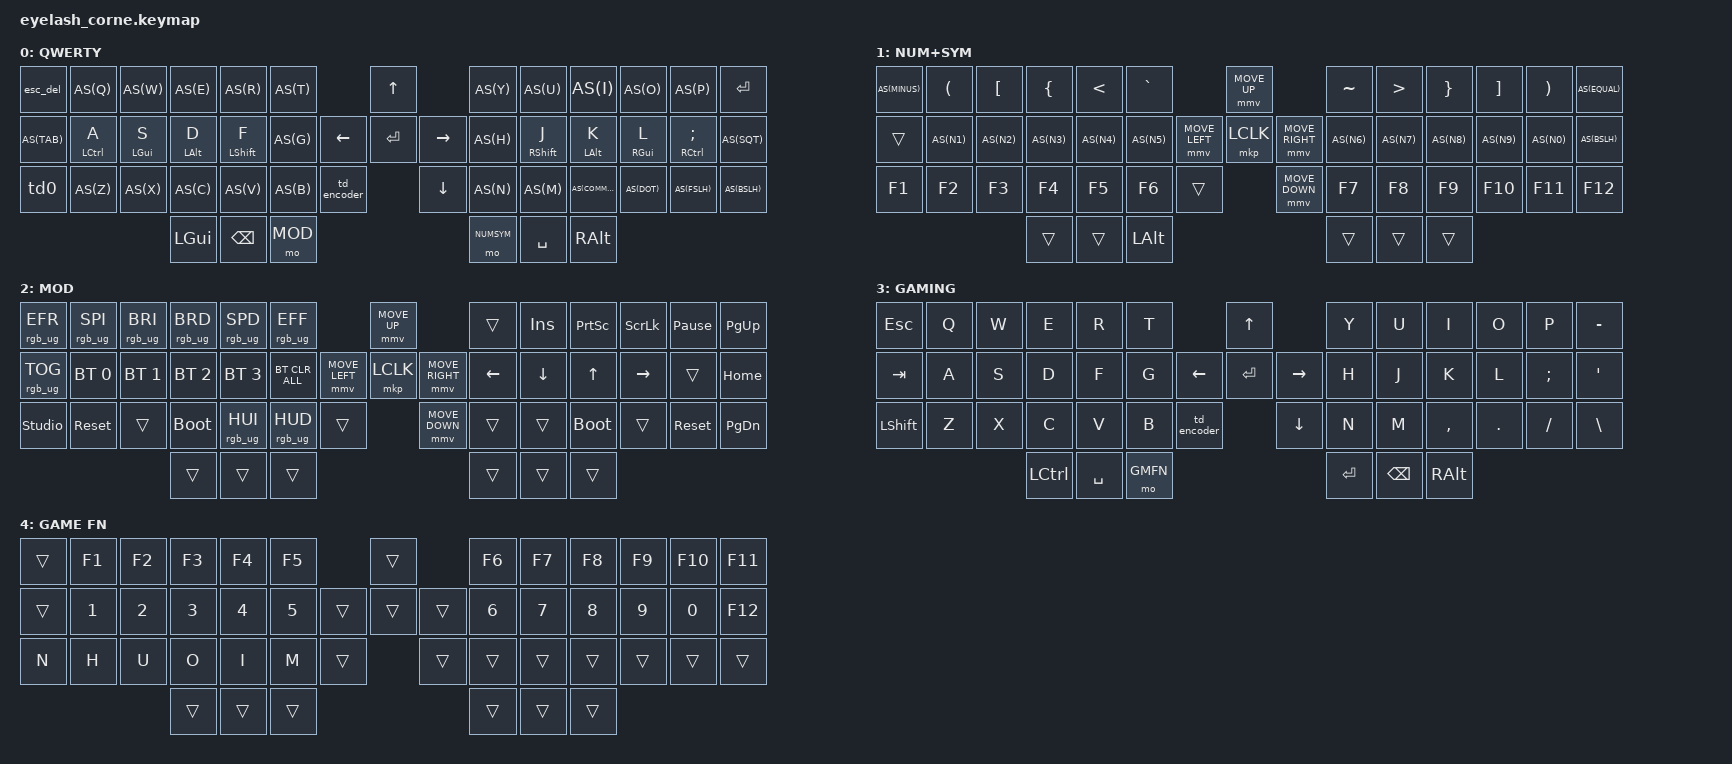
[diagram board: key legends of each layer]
// ============================================================================
// INCLUDES
// ============================================================================
#include <behaviors.dtsi>
#include <dt-bindings/zmk/keys.h>
#include <dt-bindings/zmk/bt.h>
#include <dt-bindings/zmk/outputs.h>
#include <dt-bindings/zmk/rgb.h>
#include <dt-bindings/zmk/pointing.h>
#include <input/processors.dtsi>
#include <zephyr/dt-bindings/input/input-event-codes.h>

// ============================================================================
// LAYER DEFINITIONS
// ============================================================================
#define DFLT 0
/* #define NUM 1 */
/* #define SYM 2 */
#define NUMSYM 1
/* #define MOD 3 */
#define MOD 2
/* #define GMNG 4 */
#define GMNG 3
/* #define GMFN 5 */
#define GMFN 4

// ============================================================================
// CONFIGURATION
// ============================================================================
#undef ZMK_POINTING_DEFAULT_MOVE_VAL
#define ZMK_POINTING_DEFAULT_MOVE_VAL 1200  // 600
#undef ZMK_POINTING_DEFAULT_SCRL_VAL
#define ZMK_POINTING_DEFAULT_SCRL_VAL 25    // 10

// ============================================================================
// MACROS
// ============================================================================
#define AS(keycode) &as LS(keycode) keycode     // Autoshift Macro

// ============================================================================
// INPUT LISTENERS
// ============================================================================
&mmv_input_listener { input-processors = <&zip_xy_scaler 2 1>; };

&msc_input_listener { input-processors = <&zip_scroll_scaler 2 1>; };

// ============================================================================
// MOUSE SCROLL CONFIGURATION
// ============================================================================
&msc {
    acceleration-exponent = <1>;      // 0
    time-to-max-speed-ms = <100>;     // 300
    delay-ms = <0>;                   // 0
};

// ============================================================================
// MOUSE MOVEMENT CONFIGURATION
// ============================================================================
&mmv {
    time-to-max-speed-ms = <500>;
    acceleration-exponent = <1>;
    trigger-period-ms = <16>;
};

// // ============================================================================
// // ENCODER CONFIGURATION
// // ============================================================================
// &sensors {
//     compatible = "alps,ec11";
//     steps = <30>;
// };

// ============================================================================
// SOFT OFF CONFIGURATION
// ============================================================================
&soft_off { hold-time-ms = <2000>; };

// ============================================================================
// Layout Numbering
// ============================================================================
// 0=td_esc   1=Q      2=W      3=E      4=R      5=T      6=UP      7=Y      8=U      9=I     10=O     11=P     12=ENTER
// 13=TAB     14=A     15=S     16=D     17=F     18=G     19=LEFT   20=ENTER 21=RIGHT 22=H     23=J     24=K     25=L     26=;     27='
// 28=td0     29=Z     30=X     31=C     32=V     33=B     34=td_enc 35=DOWN           36=N     37=M     38=,     39=.     40=/     41=\
//                                       42=GUI   43=BSPC  44=MOD                      45=NUMSYM 46=SPACE 47=ALT

// ============================================================================
// DEVICE TREE ROOT
// ============================================================================
/ {
    macros {
        // Ctrl+Alt+Del macro
        cad: ctrl_alt_del {
            compatible = "zmk,behavior-macro";
            #binding-cells = <0>;
            bindings = <&kp LC(LA(DEL))>;
        };
    };

    behaviors {
        // Auto Shift
        as: auto_shift {
            compatible = "zmk,behavior-hold-tap";
            #binding-cells = <2>;
            tapping_term_ms = <175>;
            quick_tap_ms = <0>;
            flavor = "tap-preferred";
            bindings = <&kp>, <&kp>;
        };

        // Home Row Mods
        hml: home_row_mod_left {
            compatible = "zmk,behavior-hold-tap";
            #binding-cells = <2>;
            flavor = "balanced";
            require-prior-idle-ms = <150>;
            tapping-term-ms = <280>;
            quick-tap-ms = <175>;
            bindings = <&kp>, <&kp>;
            // Right side keys (positions 6-12, 19-27, 34-41, 45-47)
            hold-trigger-key-positions = <6 7 8 9 10 11 12 19 20 21 22 23 24 25 26 27 34 35 36 37 38 39 40 41 45 46 47>;
            hold-trigger-on-release;
        };
        hmr: home_row_mod_right {
            compatible = "zmk,behavior-hold-tap";
            #binding-cells = <2>;
            flavor = "balanced";
            require-prior-idle-ms = <150>;
            tapping-term-ms = <280>;
            quick-tap-ms = <175>;
            bindings = <&kp>, <&kp>;
            // Left side keys (positions 0-5, 13-18, 28-33, 42-44)
            hold-trigger-key-positions = <0 1 2 3 4 5 13 14 15 16 17 18 28 29 30 31 32 33 42 43 44>;
            hold-trigger-on-release;
        };

        // escape/delete mod-morph
        esc_del: esc_del {
            compatible = "zmk,behavior-mod-morph";
            #binding-cells = <0>;
            bindings = <&kp ESC>, <&kp DEL>;
            mods = <(MOD_LSFT|MOD_RSFT)>;
        };

        // Tap Dance
        td0: td0 {
            compatible = "zmk,behavior-tap-dance";
            display-name = "Shift/Caps Lock Tap Dance";
            #binding-cells = <0>;
            tapping-term-ms = <280>;
            bindings = <&kp LEFT_SHIFT>, <&kp CAPS>;
        };
        td_esc: td_esc {
            compatible = "zmk,behavior-tap-dance";
            display-name = "ESC/Delete Tap Dance";
            #binding-cells = <0>;
            tapping-term-ms = <280>;
            bindings = <&kp ESC>, <&kp DEL>;
        };
        td_encoder: td_encoder {
            compatible = "zmk,behavior-tap-dance";
            display-name = "Encoder Mute/Pause Tap Dance";
            #binding-cells = <0>;
            tapping-term-ms = <280>;
            bindings = <&kp K_PLAY_PAUSE>, <&kp K_MUTE>;
        };


        // Encoder behaviors
        rgb_encoder: rgb_encoder {
            compatible = "zmk,behavior-sensor-rotate";
            #sensor-binding-cells = <0>;
            bindings = <&rgb_ug RGB_BRI>, <&rgb_ug RGB_BRD>;
        };
        scroll_encoder: scroll_encoder {
            compatible = "zmk,behavior-sensor-rotate";
            #sensor-binding-cells = <0>;
            bindings = <&msc SCRL_DOWN>, <&msc SCRL_UP>;

            // tap-ms = <50>;
        };
    };

    combos {
        compatible = "zmk,combos";

        softoff {
            bindings = <&soft_off>;
            key-positions = <1 15 29>;
        };

        gaming_toggle {
            bindings = <&tog GMNG>;
            key-positions = <43 46>;  // both layer keys
            timeout-ms = <50>;
            layers = <0 3>;
        };

        ctrl_alt_del_combo {
            bindings = <&cad>;
            key-positions = <23 24 25>; // three finger salute
            timeout-ms = <50>;
            layers = <0>;
        };

        undo_combo {
            bindings = <&kp LC(Z)>;  // Ctrl+Z
            key-positions = <28 29>; // Shift+Z
            timeout-ms = <50>;
            layers = <0>;
        };

        redo_combo {
            bindings = <&kp LC(LS(Z))>;  // Ctrl+Shift+Z
            key-positions = <28 33>; // Shift+B
            timeout-ms = <50>;
            layers = <0>;
        };

        cut_combo {
            bindings = <&kp LC(LS(X))>;  // Ctrl+Shift+X
            key-positions = <28 30>; // Shift+X
            timeout-ms = <50>;
            layers = <0>;
        };

        copy_combo {
            bindings = <&kp LC(LS(C))>;  // Ctrl+Shift+C
            key-positions = <28 31>; // Shift+C
            timeout-ms = <50>;
            layers = <0>;
        };

        paste_combo {
            bindings = <&kp LC(LS(V))>;  // Ctrl+Shift+V
            key-positions = <28 32>; // Shift+V
            timeout-ms = <50>;
            layers = <0>;
        };
    };

    keymap {
        compatible = "zmk,keymap";

        default_layer {
            display-name = "QWERTY";
            bindings = <
                // ╭─────────┬──────────────┬──────────────┬──────────────┬──────────────┬──────────────╮                   ╭───────────────╮                   ╭────────────┬─────────────┬───────────┬───────────┬─────────────┬───────────╮
                     &esc_del      AS(Q)          AS(W)          AS(E)          AS(R)          AS(T)                              &kp UP                           AS(Y)          AS(U)        AS(I)      AS(O)        AS(P)       &kp ENTER
                // │ES/DL/CAD│      Q       │      W       │      E       │      R       │      T       │                   │       ↑       │                   │    Y       │      U      │     I     │    O      │     P       │ ENTER     │
                // ├─────────┼──────────────┼──────────────┼──────────────┼──────────────┼──────────────┤ ╭─────────────────┼───────────────┼─────────────────╮ ├────────────┼─────────────┼───────────┼───────────┼─────────────┼───────────┤
                     AS(TAB)   &hml LCTRL A    &hml LGUI S    &hml LALT D   &hml LSHIFT F   AS(G)              &kp LEFT          &kp ENTER       &kp RIGHT         AS(H)      &hmr RSHIFT J &hmr LALT K &hmr RGUI L &hmr RCTRL SEMI  AS(SQT)
                // │  TAB    │   A/CTRL     │   S/GUI      │    D/ALT     │   F/SHIFT    │      G       │ │        ←        │     ENTER     │        →        │ │    H       │   J/SHIFT   │   K/ALT   │  L/GUI    │     ;/CTRL  │     '     │
                // ├─────────┼──────────────┼──────────────┼──────────────┼──────────────┼──────────────┤ ╰─────────────────┼───────────────┼─────────────────╯ ├────────────┼─────────────┼───────────┼───────────┼─────────────┼───────────┤
                     &td0         AS(Z)          AS(X)          AS(C)          AS(V)          AS(B)         &td_encoder         &kp DOWN                          AS(N)          AS(M)       AS(COMMA)    AS(DOT)      AS(FSLH)     AS(BSLH)
                // │ SHIFT/CL│      Z       │      X       │      C       │      V       │      B       │    PLAY/MUTE      │       ↓       │                   │    N       │      M      │      ,    │     .     │      /      │     \     │
                // ╰─────────┴──────────────┴──────────────┼──────────────┼──────────────┼──────────────┤                   ╰───────────────╯                   ├────────────┼─────────────┼───────────┼───────────┴─────────────┴───────────╯
                                                                &kp LGUI       &kp BSPC        &mo MOD                                                            &mo NUMSYM    &kp SPACE     &kp RALT
                //                                         │      GUI     │     BSPC     │   LAYER2     │                                                       │ LAYER1     │    SPACE    │    ALT    │
                //                                         ╰──────────────┴──────────────┴──────────────╯                                                       ╰────────────┴─────────────┴───────────╯
            >;

            sensor-bindings = <&inc_dec_kp C_VOL_UP C_VOL_DN>;  // 🔊 Volume control
        };

        numsym_layer {
            display-name = "NUM+SYM";
            bindings = <
                // ╭────────┬──────────┬──────────┬──────────┬────────┬───────────╮                   ╭───────────────╮                   ╭───────────┬────────┬──────────┬──────────┬──────────┬───────────╮
                   AS(MINUS)  &kp LPAR   &kp LBKT   &kp LBRC   &kp LT   &kp GRAVE                        &mmv MOVE_UP                       &kp TILDE   &kp GT   &kp RBRC   &kp RBKT   &kp RPAR   AS(EQUAL)
                // │ - / _  │     (    │     [    │    {     │   <    │     `     │                   │       ↑       │                   │      ~    │    >   │     }    │     ]    │     )    │   = / +   │
                // ├────────┼──────────┼──────────┼──────────┼────────┼───────────┤ ╭─────────────────┼───────────────┼─────────────────╮ ├───────────┼────────┼──────────┼──────────┼──────────┼───────────┤
                     &trans    AS(N1)     AS(N2)     AS(N3)     AS(N4)    AS(N5)       &mmv MOVE_LEFT     &mkp LCLK     &mmv MOVE_RIGHT      AS(N6)     AS(N7)    AS(N8)     AS(N9)     AS(N0)    AS(BSLH)
                // │  TAB   │  1 / !   │  2 / @   │  3 / #   │  4 / $ │   5 / %   │ │        ←        │     CLICK     │        →        │ │   6 / ^   │  7 / & │   8 / *  │   9 / (  │   0 / )  │   \ / |   │
                // ├────────┼──────────┼──────────┼──────────┼────────┼───────────┤ ╰─────────────────┼───────────────┼─────────────────╯ ├───────────┼────────┼──────────┼──────────┼──────────┼───────────┤
                     &kp F1    &kp F2     &kp F3     &kp F4     &kp F5    &kp F6           &trans         &mmv MOVE_DOWN                     &kp F7     &kp F8    &kp F9     &kp F10    &kp F11    &kp F12
                // │   F1   │    F2    │    F3    │    F4    │     F5 │      F6   │    PLAY/MUTE      │       ↓       │                   │     F7    │    F8  │     F9   │     F10  │     F11  │     F12   │
                // ╰────────┴──────────┴──────────┼──────────┼────────┼───────────┤                   ╰───────────────╯                   ├───────────┼────────┼──────────┼──────────┴──────────┴───────────╯
                                                     &trans    &trans   &kp LALT                                                             &trans     &trans    &trans
                //                                │      GUI │   BSPC │   LALT    │                                                       │   ^^^^    │ SPACE  │   ALT    │
                //                                ╰──────────┴────────┴───────────╯                                                       ╰───────────┴────────┴──────────╯
            >;

            sensor-bindings = <&inc_dec_kp C_BRI_UP C_BRI_DN>;  // 🔆 Brightness control
        };

        mod_layer {
            display-name = "MOD";
            bindings = <
                // ╭───────────────┬───────────────┬───────────────┬───────────────┬───────────────┬───────────────╮                  ╭───────────────╮                   ╭────────┬────────┬──────────────┬──────────────┬──────────────┬──────────╮
                    &rgb_ug RGB_EFR &rgb_ug RGB_SPI &rgb_ug RGB_BRI &rgb_ug RGB_BRD &rgb_ug RGB_SPD &rgb_ug RGB_EFF                     &mmv MOVE_UP                        &trans  &kp INS &kp PRINTSCREEN &kp SCROLLLOCK &kp PAUSE_BREAK &kp PG_UP
                // │   RGB EFR     │   RGB SPI     │   RGB BRI     │   RGB BRD     │    RGB SPD    │    RGB EFF    │                  │       ↑       │                   │  ---   │ INS    │   PRTSCRN    │   SCRLCK     │ PAUSE BREAK  │  PG UP   │
                // ├───────────────┼───────────────┼───────────────┼───────────────┼───────────────┼───────────────┤ ╭────────────────┼───────────────┼─────────────────╮ ├────────┼────────┼──────────────┼──────────────┼──────────────┼──────────┤
                    &rgb_ug RGB_TOG  &bt BT_SEL 0    &bt BT_SEL 1     &bt BT_SEL 2    &bt BT_SEL 3   &bt BT_CLR_ALL    &mmv MOVE_LEFT     &mkp LCLK     &mmv MOVE_RIGHT    &kp LEFT &kp DOWN    &kp UP         &kp RIGHT      &trans       &kp HOME
                // │   RGB TOG     │    BT 0       │    BT 1       │     BT 2      │     BT 3      │     BT CLR    │ │       ←        │     CLICK     │        →        │ │    ←   │    ↓   │       ↑      │       →      │     ---      │   HOME   │
                // ├───────────────┼───────────────┼───────────────┼───────────────┼───────────────┼───────────────┤ ╰────────────────┼───────────────┼─────────────────╯ ├────────┼────────┼──────────────┼──────────────┼──────────────┼──────────┤
                    &studio_unlock    &sys_reset       &trans        &bootloader    &rgb_ug RGB_HUI &rgb_ug RGB_HUD     &trans          &mmv MOVE_DOWN                      &trans   &trans    &bootloader      &trans        &sys_reset   &kp PG_DN
                // │STUDIO UNLOCK  │  SYS RST      │   ---         │  BOOTLOADER   │    RGB HUI    │    RGB HUD    │   PLAY/MUTE      │       ↓       │                   │  ---   │  ---   │ BOOTLOADER   │     ---      │   SYS RST    │   PG DN  │
                // ╰───────────────┴───────────────┴───────────────┼───────────────┼───────────────┼───────────────┤                  ╰───────────────╯                   ├────────┼────────┼──────────────┼──────────────┴──────────────┴──────────╯
                                                                         &trans           &trans         &trans                                                             &trans   &trans      &trans
                //                                                 │     ^^^^      │      BSPC     │      MOD      │                                                      │SYMLAYER│ SPACE  │     ALT      │
                //                                                 ╰───────────────┴───────────────┴───────────────╯                                                      ╰────────┴────────┴──────────────╯
            >;

            sensor-bindings = <&scroll_encoder>;  // 📜 Scroll control
        };

        gaming_layer {
            display-name = "GAMING";
            bindings = <
                // ╭────────┬────────┬────────┬────────┬────────┬────────╮                   ╭───────────────╮                   ╭────────┬────────┬────────┬────────┬────────┬────────╮
                    &kp ESC   &kp Q    &kp W    &kp E    &kp R    &kp T                            &kp UP                          &kp Y    &kp U    &kp I    &kp O    &kp P    &kp MINUS
                // │  ESC   │   Q    │   W    │   E    │   R    │   T    │                   │       ↑       │                   │   Y    │   U    │   I    │   O    │   P    │   -    │
                // ├────────┼────────┼────────┼────────┼────────┼────────┤ ╭─────────────────┼───────────────┼─────────────────╮ ├────────┼────────┼────────┼────────┼────────┼────────┤
                     &kp TAB  &kp A    &kp S    &kp D    &kp F    &kp G        &kp LEFT          &kp ENTER      &kp RIGHT          &kp H    &kp J    &kp K    &kp L    &kp SEMI &kp SQT
                // │  TAB   │   A    │   S    │   D    │   F    │   G    │ │        ←        │     ENTER     │        →        │ │   H    │   J    │   K    │   L    │   ;    │   '    │
                // ├────────┼────────┼────────┼────────┼────────┼────────┤ ╰─────────────────┼───────────────┼─────────────────╯ ├────────┼────────┼────────┼────────┼────────┼────────┤
                     &kp LSHIFT &kp Z  &kp X    &kp C    &kp V    &kp B        &td_encoder       &kp DOWN                          &kp N    &kp M    &kp COMMA &kp DOT &kp FSLH &kp BSLH
                // │ SHIFT  │   Z    │   X    │   C    │   V    │   B    │       MUTE        │       ↓       │                   │   N    │   M    │   ,    │   .    │   /    │   \    │
                // ╰────────┴────────┴────────┼────────┼────────┼────────┤                   ╰───────────────╯                   ├────────┼────────┼────────┼────────┴────────┴────────╯
                                                &kp LCTRL &kp SPACE &mo GMFN                                                       &kp ENTER &kp BSPC &kp RALT
                //                            │  CTRL  │  SPACE │ GAMEFN │                                                       │ ENTER  │  BSPC  │  ALT   │
                //                            ╰────────┴────────┴────────╯                                                       ╰────────┴────────┴────────╯
            >;

            sensor-bindings = <&scroll_encoder>;  // 📜 Scroll control
        };

        gaming_fn_layer {
            display-name = "GAME FN";
            bindings = <
                // ╭────────┬────────┬────────┬────────┬────────┬────────╮                   ╭───────────────╮                   ╭────────┬────────┬────────┬────────┬────────┬────────╮
                     &trans   &kp F1   &kp F2   &kp F3   &kp F4   &kp F5                         &trans                            &kp F6   &kp F7   &kp F8   &kp F9   &kp F10  &kp F11
                // │  ESC   │   F1   │   F2   │   F3   │   F4   │   F5   │                   │       ↑       │                   │   F6   │   F7   │   F8   │   F9   │  F10   │  F11   │
                // ├────────┼────────┼────────┼────────┼────────┼────────┤ ╭─────────────────┼───────────────┼─────────────────╮ ├────────┼────────┼────────┼────────┼────────┼────────┤
                     &trans   &kp N1   &kp N2   &kp N3   &kp N4   &kp N5       &trans           &trans           &trans            &kp N6   &kp N7   &kp N8   &kp N9   &kp N0   &kp F12
                // │  TAB   │   1    │   2    │   3    │   4    │   5    │ │        ←        │     ENTER     │        →        │ │   6    │   7    │   8    │   9    │   0    │  F12   │
                // ├────────┼────────┼────────┼────────┼────────┼────────┤ ╰─────────────────┼───────────────┼─────────────────╯ ├────────┼────────┼────────┼────────┼────────┼────────┤
                     &kp N    &kp H    &kp U    &kp O    &kp I    &kp M        &trans            &trans                            &trans   &trans   &trans   &trans   &trans   &trans
                // │   N    │   H    │   U    │   O    │   I    │   M    │       MUTE        │       ↓       │                   │        │        │        │        │        │   \    │
                // ╰────────┴────────┴────────┼────────┼────────┼────────┤                   ╰───────────────╯                   ├────────┼────────┼────────┼────────┴────────┴────────╯
                                                &trans   &trans   &trans                                                           &trans   &trans   &trans
                //                            │  CTRL  │  SPACE │ ^^^^   │                                                       │ ENTER  │  BSPC  │  ALT   │
                //                            ╰────────┴────────┴────────╯                                                       ╰────────┴────────┴────────╯
            >;

            sensor-bindings = <&inc_dec_kp C_VOL_UP C_VOL_DN>;  // 🔊 Volume control
        };
    };
};
